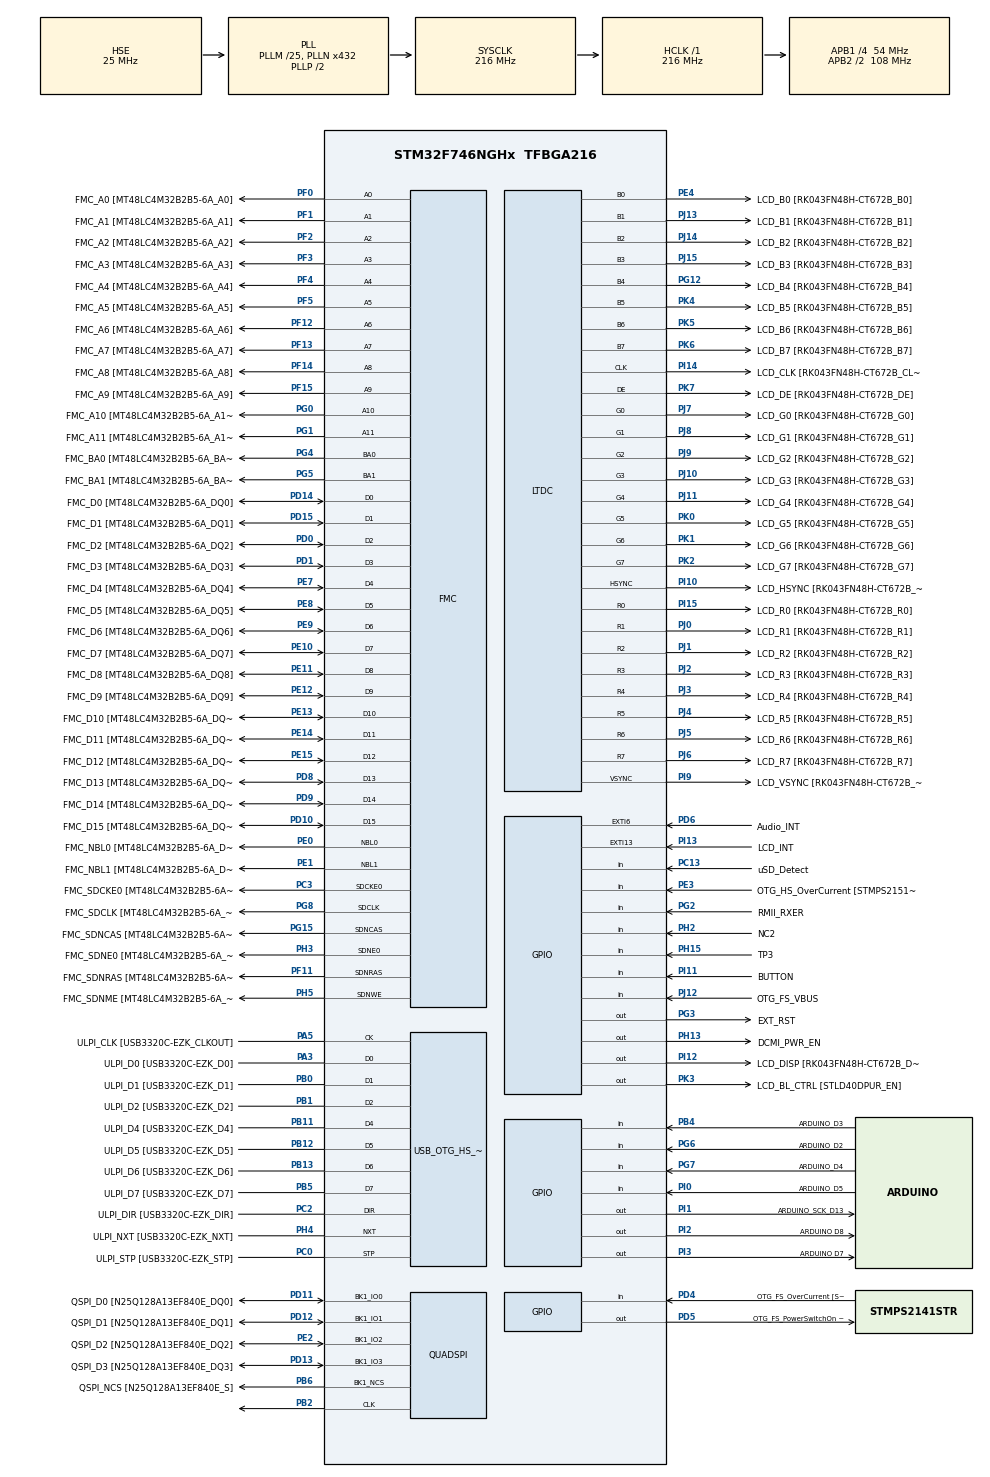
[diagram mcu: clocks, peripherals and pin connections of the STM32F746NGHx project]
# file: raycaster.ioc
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CORTEX_M7.ART_ACCELERATOR_ENABLE=1
CORTEX_M7.CPU_DCache=Enabled
CORTEX_M7.CPU_ICache=Enabled
CORTEX_M7.FlashInterface=TCM_Enabled
DMA2D.ColorMode=DMA2D_OUTPUT_RGB565
FMC.CASLatency1=FMC_SDRAM_CAS_LATENCY_3
FMC.ExitSelfRefreshDelay1=7
FMC.LoadToActiveDelay1=2
FMC.RCDDelay1=2
FMC.RPDelay1=2
FMC.RPDelay2=2
FMC.ReadBurst1=FMC_SDRAM_RBURST_ENABLE
FMC.ReadBurst2=FMC_SDRAM_RBURST_ENABLE
FMC.RowCycleDelay1=7
FMC.RowCycleDelay2=7
FMC.SDClockPeriod1=FMC_SDRAM_CLOCK_PERIOD_2
FMC.SDClockPeriod2=FMC_SDRAM_CLOCK_PERIOD_2
FMC.SelfRefreshTime1=4
FMC.WriteRecoveryTime1=3
LTDC.ActiveH=272
LTDC.ActiveW=480
LTDC.Alpha_L0=255
LTDC.BlendingFactor1_L0=LTDC_BLENDING_FACTOR1_PAxCA
LTDC.BlendingFactor2_L0=LTDC_BLENDING_FACTOR2_PAxCA
LTDC.Blue=0
LTDC.FBStartAdress_L0=0xC0000000
LTDC.Green=0
LTDC.HBP=13
LTDC.HFP=32
LTDC.HSync=41
LTDC.ImageHeight_L0=272
LTDC.ImageWidth_L0=480
LTDC.Layers=0
LTDC.PixelFormat_L0=LTDC_PIXEL_FORMAT_RGB888
LTDC.Red=0
LTDC.VSync=10
LTDC.WindowX1_L0=480
LTDC.WindowY1_L0=272
Mcu.Family=STM32F7
Mcu.Name=STM32F746NGHx
Mcu.Package=TFBGA216
NVIC.DMA2D_IRQn=true\:0\:0\:false\:false\:true\:true\:true\:true
NVIC.LTDC_IRQn=true\:0\:0\:false\:false\:true\:true\:true\:true
NVIC.PriorityGroup=NVIC_PRIORITYGROUP_4
NVIC.TIM6_DAC_IRQn=true\:15\:0\:false\:false\:true\:false\:true\:true
NVIC.TimeBase=TIM6_DAC_IRQn
NVIC.TimeBaseIP=TIM6
PA0/WKUP.GPIO_Label=ARDUINO A0
PA0/WKUP.GPIO_Mode=GPIO_MODE_ANALOG
PA0/WKUP.GPIO_PuPd=GPIO_NOPULL
PA0/WKUP.Signal=ADCx_IN0
PA1.GPIO_Label=RMII_REF_CLK [LAN8742A-CZ-TR_REFCLK0]
PA1.Signal=ETH_REF_CLK
PA10.GPIO_Label=OTG_FS_ID
PA10.Signal=USB_OTG_FS_ID
PA11.GPIO_Label=OTG_FS_N
PA11.Signal=USB_OTG_FS_DM
PA12.GPIO_Label=OTG_FS_P
PA12.Signal=USB_OTG_FS_DP
PA13.GPIO_Label=SWDIO
PA13.Mode=Serial_Wire
PA13.Signal=SYS_JTMS-SWDIO
PA14.GPIO_Label=SWCLK
PA14.Mode=Serial_Wire
PA14.Signal=SYS_JTCK-SWCLK
PA15.GPIO_Label=ARDUINO PWM/D9
PA15.GPIO_ModeDefaultPP=GPIO_MODE_AF_PP
PA15.GPIO_PuPd=GPIO_NOPULL
PA15.GPIO_Speed=GPIO_SPEED_FREQ_LOW
PA15.Signal=S_TIM2_CH1_ETR
PA2.GPIO_Label=RMII_MDIO [LAN8742A-CZ-TR_MDIO]
PA2.Signal=ETH_MDIO
PA3.GPIO_Label=ULPI_D0 [USB3320C-EZK_D0]
PA3.Mode=Host_HS
PA3.Signal=USB_OTG_HS_ULPI_D0
PA4.GPIO_Label=DCMI_HSYNC
PA4.Signal=DCMI_HSYNC
PA5.GPIO_Label=ULPI_CLK [USB3320C-EZK_CLKOUT]
PA5.Mode=Host_HS
PA5.Signal=USB_OTG_HS_ULPI_CK
PA6.Signal=DCMI_PIXCLK
PA7.GPIO_Label=RMII_CRS_DV [LAN8742A-CZ-TR_CRS_DV]
PA7.Signal=ETH_CRS_DV
PA8.GPIO_Label=ARDUINO PWM/D10
PA8.GPIO_ModeDefaultPP=GPIO_MODE_AF_PP
PA8.GPIO_PuPd=GPIO_NOPULL
PA8.GPIO_Speed=GPIO_SPEED_FREQ_LOW
PA8.Signal=S_TIM1_CH1
PA9.GPIO_Label=VCP_TX [STM32F103CBT6_PA3]
PA9.GPIO_Mode=GPIO_MODE_AF_PP
PA9.GPIO_PuPd=GPIO_NOPULL
PA9.GPIO_Speed=GPIO_SPEED_FREQ_LOW
PA9.Signal=USART1_TX
PB0.GPIO_Label=ULPI_D1 [USB3320C-EZK_D1]
PB0.Mode=Host_HS
PB0.Signal=USB_OTG_HS_ULPI_D1
PB1.GPIO_Label=ULPI_D2 [USB3320C-EZK_D2]
PB1.Mode=Host_HS
PB1.Signal=USB_OTG_HS_ULPI_D2
PB10.GPIO_Label=ULPI_D3 [USB3320C-EZK_D3]
PB10.Signal=USB_OTG_HS_ULPI_D3
PB11.GPIO_Label=ULPI_D4 [USB3320C-EZK_D4]
PB11.Mode=Host_HS
PB11.Signal=USB_OTG_HS_ULPI_D4
PB12.GPIO_Label=ULPI_D5 [USB3320C-EZK_D5]
PB12.Mode=Host_HS
PB12.Signal=USB_OTG_HS_ULPI_D5
PB13.GPIO_Label=ULPI_D6 [USB3320C-EZK_D6]
PB13.Mode=Host_HS
PB13.Signal=USB_OTG_HS_ULPI_D6
PB14.GPIO_Label=ARDUINO MISO/D12
PB14.GPIO_Mode=GPIO_MODE_AF_PP
PB14.GPIO_PuPd=GPIO_NOPULL
PB14.GPIO_Speed=GPIO_SPEED_FREQ_LOW
PB14.Signal=SPI2_MISO
PB15.GPIO_Label=ARDUINO MOSI/PWM/D11
PB15.GPIO_Mode=GPIO_MODE_AF_PP
PB15.GPIO_PuPd=GPIO_NOPULL
PB15.GPIO_Speed=GPIO_SPEED_FREQ_LOW
PB15.Signal=SPI2_MOSI
PB2.Mode=Single Bank 1
PB2.Signal=QUADSPI_CLK
PB3.GPIO_Label=SWO
PB3.Signal=SYS_JTDO-SWO
PB4.GPIO_Label=ARDUINO_D3
PB4.Signal=GPIO_Input
PB5.GPIO_Label=ULPI_D7 [USB3320C-EZK_D7]
PB5.Mode=Host_HS
PB5.Signal=USB_OTG_HS_ULPI_D7
PB6.GPIO_Label=QSPI_NCS [N25Q128A13EF840E_S]
PB6.Mode=Single Bank 1
PB6.Signal=QUADSPI_BK1_NCS
PB7.GPIO_Label=VCP_RX [STM32F103CBT6_PA2]
PB7.GPIO_Mode=GPIO_MODE_AF_PP
PB7.GPIO_PuPd=GPIO_NOPULL
PB7.GPIO_Speed=GPIO_SPEED_FREQ_LOW
PB7.Signal=USART1_RX
PB8.GPIO_Label=ARDUINO SCL/D15
PB8.GPIO_Mode=GPIO_MODE_AF_OD
PB8.GPIO_Pu=GPIO_PULLUP
PB8.GPIO_PuPd=GPIO_NOPULL
PB8.GPIO_Speed=GPIO_SPEED_FREQ_LOW
PB8.Signal=I2C1_SCL
PB9.GPIO_Label=ARDUINO SDA/D14
PB9.GPIO_Mode=GPIO_MODE_AF_OD
PB9.GPIO_Pu=GPIO_PULLUP
PB9.GPIO_PuPd=GPIO_NOPULL
PB9.GPIO_Speed=GPIO_SPEED_FREQ_LOW
PB9.Signal=I2C1_SDA
PC0.GPIO_Label=ULPI_STP [USB3320C-EZK_STP]
PC0.Mode=Host_HS
PC0.Signal=USB_OTG_HS_ULPI_STP
PC1.GPIO_Label=RMII_MDC [LAN8742A-CZ-TR_MDC]
PC1.Signal=ETH_MDC
PC10.GPIO_Label=SDMMC_D2
PC10.Signal=SDMMC1_D2
PC11.GPIO_Label=SDMMC_D3
PC11.Signal=SDMMC1_D3
PC12.GPIO_Label=SDMMC_CK
PC12.Signal=SDMMC1_CK
PC13.GPIO_Label=uSD_Detect
PC13.Signal=GPIO_Input
PC14/OSC32_IN.GPIO_Label=RCC_OSC32_IN
PC14/OSC32_IN.Mode=LSE-External-Oscillator
PC14/OSC32_IN.Signal=RCC_OSC32_IN
PC15/OSC32_OUT.GPIO_Label=RCC_OSC32_OUT
PC15/OSC32_OUT.Mode=LSE-External-Oscillator
PC15/OSC32_OUT.Signal=RCC_OSC32_OUT
PC2.GPIO_Label=ULPI_DIR [USB3320C-EZK_DIR]
PC2.Mode=Host_HS
PC2.Signal=USB_OTG_HS_ULPI_DIR
PC3.GPIO_Label=FMC_SDCKE0 [MT48LC4M32B2B5-6A_CKE]
PC3.Mode=SdramChipSelect1_1
PC3.Signal=FMC_SDCKE0
PC4.GPIO_Label=RMII_RXD0 [LAN8742A-CZ-TR_RXD0]
PC4.Signal=ETH_RXD0
PC5.GPIO_Label=RMII_RXD1 [LAN8742A-CZ-TR_RXD1]
PC5.Signal=ETH_RXD1
PC6.GPIO_Label=ARDUINO TX/D1
PC6.Signal=USART6_TX
PC7.GPIO_Label=ARDUINO RX/D0
PC7.Signal=USART6_RX
PC8.Signal=SDMMC1_D0
PC9.Signal=SDMMC1_D1
PD0.GPIO_Label=FMC_D2 [MT48LC4M32B2B5-6A_DQ2]
PD0.Signal=FMC_D2_DA2
PD1.GPIO_Label=FMC_D3 [MT48LC4M32B2B5-6A_DQ3]
PD1.Signal=FMC_D3_DA3
PD10.GPIO_Label=FMC_D15 [MT48LC4M32B2B5-6A_DQ15]
PD10.Signal=FMC_D15_DA15
PD11.GPIO_Label=QSPI_D0 [N25Q128A13EF840E_DQ0]
PD11.Mode=Single Bank 1
PD11.Signal=QUADSPI_BK1_IO0
PD12.GPIO_Label=QSPI_D1 [N25Q128A13EF840E_DQ1]
PD12.Mode=Single Bank 1
PD12.Signal=QUADSPI_BK1_IO1
PD13.GPIO_Label=QSPI_D3 [N25Q128A13EF840E_DQ3]
PD13.Mode=Single Bank 1
PD13.Signal=QUADSPI_BK1_IO3
PD14.GPIO_Label=FMC_D0 [MT48LC4M32B2B5-6A_DQ0]
PD14.Signal=FMC_D0_DA0
PD15.GPIO_Label=FMC_D1 [MT48LC4M32B2B5-6A_DQ1]
PD15.Signal=FMC_D1_DA1
PD2.GPIO_Label=SDMMC_CMD
PD2.GPIO_Speed_High_Default=GPIO_SPEED_FREQ_VERY_HIGH
PD2.Signal=SDMMC1_CMD
PD3.GPIO_Label=DCMI_D5
PD3.Signal=DCMI_D5
PD4.GPIO_Label=OTG_FS_OverCurrent [STMPS2141STR_Fault]
PD4.Signal=GPIO_Input
PD5.GPIO_Label=OTG_FS_PowerSwitchOn [STMPS2141STR_EN]
PD5.PinState=GPIO_PIN_SET
PD5.Signal=GPIO_Output
PD6.GPIO_Label=Audio_INT
PD6.GPIO_ModeDefaultEXTI=GPIO_MODE_EVT_RISING
PD6.Signal=GPXTI6
PD7.GPIO_Label=SPDIF_RX0 [74LVC1G04SE_4]
PD7.Signal=SPDIFRX_IN0
PD8.GPIO_Label=FMC_D13 [MT48LC4M32B2B5-6A_DQ13]
PD8.Signal=FMC_D13_DA13
PD9.GPIO_Label=FMC_D14 [MT48LC4M32B2B5-6A_DQ14]
PD9.Signal=FMC_D14_DA14
PE0.GPIO_Label=FMC_NBL0 [MT48LC4M32B2B5-6A_DQM0]
PE0.Signal=FMC_NBL0
PE1.GPIO_Label=FMC_NBL1 [MT48LC4M32B2B5-6A_DQM1]
PE1.Signal=FMC_NBL1
PE10.GPIO_Label=FMC_D7 [MT48LC4M32B2B5-6A_DQ7]
PE10.Signal=FMC_D7_DA7
PE11.GPIO_Label=FMC_D8 [MT48LC4M32B2B5-6A_DQ8]
PE11.Signal=FMC_D8_DA8
PE12.GPIO_Label=FMC_D9 [MT48LC4M32B2B5-6A_DQ9]
PE12.Signal=FMC_D9_DA9
PE13.GPIO_Label=FMC_D10 [MT48LC4M32B2B5-6A_DQ10]
PE13.Signal=FMC_D10_DA10
PE14.GPIO_Label=FMC_D11 [MT48LC4M32B2B5-6A_DQ11]
PE14.Signal=FMC_D11_DA11
PE15.GPIO_Label=FMC_D12 [MT48LC4M32B2B5-6A_DQ12]
PE15.Signal=FMC_D12_DA12
PE2.GPIO_Label=QSPI_D2 [N25Q128A13EF840E_DQ2]
PE2.Mode=Single Bank 1
PE2.Signal=QUADSPI_BK1_IO2
PE3.GPIO_Label=OTG_HS_OverCurrent [STMPS2151STR_FAULT]
PE3.Signal=GPIO_Input
PE4.GPIO_Label=LCD_B0 [RK043FN48H-CT672B_B0]
PE4.GPIO_Speed=GPIO_SPEED_FREQ_VERY_HIGH
PE4.Mode=RGB888
PE4.Signal=LTDC_B0
PE5.GPIO_Label=DCMI_D6
PE5.Signal=DCMI_D6
PE6.GPIO_Label=DCMI_D7
PE6.Signal=DCMI_D7
PE7.GPIO_Label=FMC_D4 [MT48LC4M32B2B5-6A_DQ4]
PE7.Signal=FMC_D4_DA4
PE8.GPIO_Label=FMC_D5 [MT48LC4M32B2B5-6A_DQ5]
PE8.Signal=FMC_D5_DA5
PE9.GPIO_Label=FMC_D6 [MT48LC4M32B2B5-6A_DQ6]
PE9.Signal=FMC_D6_DA6
PF0.GPIO_Label=FMC_A0 [MT48LC4M32B2B5-6A_A0]
PF0.Signal=FMC_A0
PF1.GPIO_Label=FMC_A1 [MT48LC4M32B2B5-6A_A1]
PF1.Signal=FMC_A1
PF10.GPIO_Label=ARDUINO A1
PF10.GPIO_Mode=GPIO_MODE_ANALOG
PF10.GPIO_PuPd=GPIO_NOPULL
PF10.Signal=ADC3_IN8
PF11.GPIO_Label=FMC_SDNRAS [MT48LC4M32B2B5-6A_RAS]
PF11.Signal=FMC_SDNRAS
PF12.GPIO_Label=FMC_A6 [MT48LC4M32B2B5-6A_A6]
PF12.Signal=FMC_A6
PF13.GPIO_Label=FMC_A7 [MT48LC4M32B2B5-6A_A7]
PF13.Signal=FMC_A7
PF14.GPIO_Label=FMC_A8 [MT48LC4M32B2B5-6A_A8]
PF14.Signal=FMC_A8
PF15.GPIO_Label=FMC_A9 [MT48LC4M32B2B5-6A_A9]
PF15.Signal=FMC_A9
PF2.GPIO_Label=FMC_A2 [MT48LC4M32B2B5-6A_A2]
PF2.Signal=FMC_A2
PF3.GPIO_Label=FMC_A3 [MT48LC4M32B2B5-6A_A3]
PF3.Signal=FMC_A3
PF4.GPIO_Label=FMC_A4 [MT48LC4M32B2B5-6A_A4]
PF4.Signal=FMC_A4
PF5.GPIO_Label=FMC_A5 [MT48LC4M32B2B5-6A_A5]
PF5.Signal=FMC_A5
PF6.GPIO_Label=ARDUINO A5
PF6.GPIO_Mode=GPIO_MODE_ANALOG
PF6.GPIO_PuPd=GPIO_NOPULL
PF6.Signal=ADC3_IN4
PF7.GPIO_Label=ARDUINO A4
PF7.GPIO_Mode=GPIO_MODE_ANALOG
PF7.GPIO_PuPd=GPIO_NOPULL
PF7.Signal=ADC3_IN5
PF8.GPIO_Label=ARDUINO A3
PF8.GPIO_Mode=GPIO_MODE_ANALOG
PF8.GPIO_PuPd=GPIO_NOPULL
PF8.Signal=ADC3_IN6
PF9.GPIO_Label=ARDUINO A2
PF9.GPIO_Mode=GPIO_MODE_ANALOG
PF9.GPIO_PuPd=GPIO_NOPULL
PF9.Signal=ADC3_IN7
PG0.GPIO_Label=FMC_A10 [MT48LC4M32B2B5-6A_A10]
PG0.Signal=FMC_A10
PG1.GPIO_Label=FMC_A11 [MT48LC4M32B2B5-6A_A11]
PG1.Signal=FMC_A11
PG10.GPIO_Label=SAI2_SDB [WM8994ECS/R_ADCDAT1]
PG10.Signal=SAI2_SD_B
PG11.GPIO_Label=RMII_TX_EN [LAN8742A-CZ-TR_TXEN]
PG11.Signal=ETH_TX_EN
PG12.GPIO_Label=LCD_B4 [RK043FN48H-CT672B_B4]
PG12.GPIO_Speed=GPIO_SPEED_FREQ_VERY_HIGH
PG12.Mode=RGB888
PG12.Signal=LTDC_B4
PG13.GPIO_Label=RMII_TXD0 [LAN8742A-CZ-TR_TXD0]
PG13.Signal=ETH_TXD0
PG14.GPIO_Label=RMII_TXD1 [LAN8742A-CZ-TR_TXD1]
PG14.Signal=ETH_TXD1
PG15.GPIO_Label=FMC_SDNCAS [MT48LC4M32B2B5-6A_CAS]
PG15.Signal=FMC_SDNCAS
PG2.GPIO_Label=RMII_RXER
PG2.Signal=GPIO_Input
PG3.GPIO_Label=EXT_RST
PG3.Signal=GPIO_Output
PG4.GPIO_Label=FMC_BA0 [MT48LC4M32B2B5-6A_BA0]
PG4.Signal=FMC_A14_BA0
PG5.GPIO_Label=FMC_BA1 [MT48LC4M32B2B5-6A_BA1]
PG5.Signal=FMC_A15_BA1
PG6.GPIO_Label=ARDUINO_D2
PG6.Signal=GPIO_Input
PG7.GPIO_Label=ARDUINO_D4
PG7.Signal=GPIO_Input
PG8.GPIO_Label=FMC_SDCLK [MT48LC4M32B2B5-6A_CLK]
PG8.Signal=FMC_SDCLK
PG9.GPIO_Label=DCMI_VSYNC
PG9.Signal=DCMI_VSYNC
PH0/OSC_IN.GPIO_Label=OSC_25M [NZ2520SB-25.00M_OUT]
PH0/OSC_IN.Mode=HSE-External-Oscillator
PH0/OSC_IN.Signal=RCC_OSC_IN
PH1/OSC_OUT.Mode=HSE-External-Oscillator
PH1/OSC_OUT.Signal=RCC_OSC_OUT
PH10.GPIO_Label=DCMI_D1
PH10.Signal=DCMI_D1
PH11.GPIO_Label=DCMI_D2
PH11.Signal=DCMI_D2
PH12.GPIO_Label=DCMI_D3
PH12.Signal=DCMI_D3
PH13.GPIO_Label=DCMI_PWR_EN
PH13.Signal=GPIO_Output
PH14.GPIO_Label=DCMI_D4
PH14.Signal=DCMI_D4
PH15.GPIO_Label=TP3
PH15.Signal=GPIO_Input
PH2.GPIO_Label=NC2
PH2.Signal=GPIO_Input
PH3.GPIO_Label=FMC_SDNE0 [MT48LC4M32B2B5-6A_CS]
PH3.Mode=SdramChipSelect1_1
PH3.Signal=FMC_SDNE0
PH4.GPIO_Label=ULPI_NXT [USB3320C-EZK_NXT]
PH4.Mode=Host_HS
PH4.Signal=USB_OTG_HS_ULPI_NXT
PH5.GPIO_Label=FMC_SDNME [MT48LC4M32B2B5-6A_WE]
PH5.Signal=FMC_SDNWE
PH6.GPIO_Label=ARDUINO PWM/D6
PH6.Signal=S_TIM12_CH1
PH7.GPIO_Label=LCD_SCL [RK043FN48H-CT672B_SCL]
PH7.GPIO_Pu=GPIO_PULLUP
PH7.Signal=I2C3_SCL
PH8.GPIO_Label=LCD_SDA [RK043FN48H-CT672B_SDA]
PH8.GPIO_Pu=GPIO_PULLUP
PH8.Signal=I2C3_SDA
PH9.GPIO_Label=DCMI_D0
PH9.Signal=DCMI_D0
PI0.GPIO_Label=ARDUINO_D5
PI0.Signal=GPIO_Input
PI1.GPIO_Label=ARDUINO_SCK_D13
PI1.PinState=GPIO_PIN_SET
PI1.Signal=GPIO_Output
PI10.GPIO_Label=LCD_HSYNC [RK043FN48H-CT672B_HSYNC]
PI10.GPIO_Speed=GPIO_SPEED_FREQ_VERY_HIGH
PI10.Mode=RGB888
PI10.Signal=LTDC_HSYNC
PI11.GPIO_Label=BUTTON
PI11.Signal=GPIO_Input
PI12.GPIO_Label=LCD_DISP [RK043FN48H-CT672B_DISP] 
PI12.PinState=GPIO_PIN_SET
PI12.Signal=GPIO_Output
PI13.GPIO_Label=LCD_INT
PI13.GPIO_ModeDefaultEXTI=GPIO_MODE_EVT_RISING
PI13.Signal=GPXTI13
PI14.GPIO_Label=LCD_CLK [RK043FN48H-CT672B_CLK]
PI14.GPIO_Speed=GPIO_SPEED_FREQ_VERY_HIGH
PI14.Mode=RGB888
PI14.Signal=LTDC_CLK
PI15.GPIO_Label=LCD_R0 [RK043FN48H-CT672B_R0]
PI15.GPIO_Speed=GPIO_SPEED_FREQ_VERY_HIGH
PI15.Mode=RGB888
PI15.Signal=LTDC_R0
PI2.GPIO_Label=ARDUINO D8
PI2.Signal=GPIO_Output
PI3.GPIO_Label=ARDUINO D7
PI3.Signal=GPIO_Output
PI4.GPIO_Label=SAI2_MCLKA [WM8994ECS/R_MCLK1]
PI4.Signal=SAI2_MCLK_A
PI5.GPIO_Label=SAI2_SCKA [WM8994ECS/R_BCLK1]
PI5.Signal=SAI2_SCK_A
PI6.GPIO_Label=SAI2_SDA [WM8994ECS/R_DACDAT1]
PI6.Signal=SAI2_SD_A
PI7.GPIO_Label=SAI2_FSA [WM8994ECS/R_LRCLK1]
PI7.Signal=SAI2_FS_A
PI8.GPIO_Label=NC1 [TP2]
PI8.Signal=RTC_TS
PI9.GPIO_Label=LCD_VSYNC [RK043FN48H-CT672B_VSYNC]
PI9.GPIO_Speed=GPIO_SPEED_FREQ_VERY_HIGH
PI9.Mode=RGB888
PI9.Signal=LTDC_VSYNC
PJ0.GPIO_Label=LCD_R1 [RK043FN48H-CT672B_R1]
PJ0.GPIO_Speed=GPIO_SPEED_FREQ_VERY_HIGH
PJ0.Mode=RGB888
PJ0.Signal=LTDC_R1
PJ1.GPIO_Label=LCD_R2 [RK043FN48H-CT672B_R2]
PJ1.GPIO_Speed=GPIO_SPEED_FREQ_VERY_HIGH
PJ1.Mode=RGB888
PJ1.Signal=LTDC_R2
PJ10.GPIO_Label=LCD_G3 [RK043FN48H-CT672B_G3]
PJ10.GPIO_Speed=GPIO_SPEED_FREQ_VERY_HIGH
PJ10.Mode=RGB888
PJ10.Signal=LTDC_G3
PJ11.GPIO_Label=LCD_G4 [RK043FN48H-CT672B_G4]
PJ11.GPIO_Speed=GPIO_SPEED_FREQ_VERY_HIGH
PJ11.Mode=RGB888
PJ11.Signal=LTDC_G4
PJ12.GPIO_Label=OTG_FS_VBUS
PJ12.Signal=GPIO_Input
PJ13.GPIO_Label=LCD_B1 [RK043FN48H-CT672B_B1]
PJ13.GPIO_Speed=GPIO_SPEED_FREQ_VERY_HIGH
PJ13.Mode=RGB888
PJ13.Signal=LTDC_B1
PJ14.GPIO_Label=LCD_B2 [RK043FN48H-CT672B_B2]
PJ14.GPIO_Speed=GPIO_SPEED_FREQ_VERY_HIGH
PJ14.Mode=RGB888
PJ14.Signal=LTDC_B2
PJ15.GPIO_Label=LCD_B3 [RK043FN48H-CT672B_B3]
PJ15.GPIO_Speed=GPIO_SPEED_FREQ_VERY_HIGH
PJ15.Mode=RGB888
PJ15.Signal=LTDC_B3
PJ2.GPIO_Label=LCD_R3 [RK043FN48H-CT672B_R3]
PJ2.GPIO_Speed=GPIO_SPEED_FREQ_VERY_HIGH
PJ2.Mode=RGB888
PJ2.Signal=LTDC_R3
PJ3.GPIO_Label=LCD_R4 [RK043FN48H-CT672B_R4]
PJ3.GPIO_Speed=GPIO_SPEED_FREQ_VERY_HIGH
PJ3.Mode=RGB888
PJ3.Signal=LTDC_R4
PJ4.GPIO_Label=LCD_R5 [RK043FN48H-CT672B_R5]
PJ4.GPIO_Speed=GPIO_SPEED_FREQ_VERY_HIGH
PJ4.Mode=RGB888
PJ4.Signal=LTDC_R5
PJ5.GPIO_Label=LCD_R6 [RK043FN48H-CT672B_R6]
PJ5.GPIO_Speed=GPIO_SPEED_FREQ_VERY_HIGH
PJ5.Mode=RGB888
PJ5.Signal=LTDC_R6
PJ6.GPIO_Label=LCD_R7 [RK043FN48H-CT672B_R7]
PJ6.GPIO_Speed=GPIO_SPEED_FREQ_VERY_HIGH
PJ6.Mode=RGB888
PJ6.Signal=LTDC_R7
PJ7.GPIO_Label=LCD_G0 [RK043FN48H-CT672B_G0]
PJ7.GPIO_Speed=GPIO_SPEED_FREQ_VERY_HIGH
PJ7.Mode=RGB888
PJ7.Signal=LTDC_G0
PJ8.GPIO_Label=LCD_G1 [RK043FN48H-CT672B_G1]
PJ8.GPIO_Speed=GPIO_SPEED_FREQ_VERY_HIGH
PJ8.Mode=RGB888
PJ8.Signal=LTDC_G1
PJ9.GPIO_Label=LCD_G2 [RK043FN48H-CT672B_G2]
PJ9.GPIO_Speed=GPIO_SPEED_FREQ_VERY_HIGH
PJ9.Mode=RGB888
PJ9.Signal=LTDC_G2
PK0.GPIO_Label=LCD_G5 [RK043FN48H-CT672B_G5]
PK0.GPIO_Speed=GPIO_SPEED_FREQ_VERY_HIGH
PK0.Mode=RGB888
PK0.Signal=LTDC_G5
PK1.GPIO_Label=LCD_G6 [RK043FN48H-CT672B_G6]
PK1.GPIO_Speed=GPIO_SPEED_FREQ_VERY_HIGH
PK1.Mode=RGB888
PK1.Signal=LTDC_G6
PK2.GPIO_Label=LCD_G7 [RK043FN48H-CT672B_G7]
PK2.GPIO_Speed=GPIO_SPEED_FREQ_VERY_HIGH
PK2.Mode=RGB888
PK2.Signal=LTDC_G7
PK3.GPIO_Label=LCD_BL_CTRL [STLD40DPUR_EN]
PK3.GPIO_Speed=GPIO_SPEED_FREQ_LOW
PK3.PinState=GPIO_PIN_SET
PK3.Signal=GPIO_Output
PK4.GPIO_Label=LCD_B5 [RK043FN48H-CT672B_B5]
PK4.GPIO_Speed=GPIO_SPEED_FREQ_VERY_HIGH
PK4.Mode=RGB888
PK4.Signal=LTDC_B5
PK5.GPIO_Label=LCD_B6 [RK043FN48H-CT672B_B6]
PK5.GPIO_Speed=GPIO_SPEED_FREQ_VERY_HIGH
PK5.Mode=RGB888
PK5.Signal=LTDC_B6
PK6.GPIO_Label=LCD_B7 [RK043FN48H-CT672B_B7]
PK6.GPIO_Speed=GPIO_SPEED_FREQ_VERY_HIGH
PK6.Mode=RGB888
PK6.Signal=LTDC_B7
PK7.GPIO_Label=LCD_DE [RK043FN48H-CT672B_DE]
PK7.GPIO_Speed=GPIO_SPEED_FREQ_VERY_HIGH
PK7.Mode=RGB888
PK7.Signal=LTDC_DE
ProjectManager.HeapSize=0x200
ProjectManager.StackSize=0x400
ProjectManager.TargetToolchain=STM32CubeIDE
QUADSPI.ChipSelectHighTime=QSPI_CS_HIGH_TIME_6_CYCLE
QUADSPI.ClockPrescaler=1
QUADSPI.FifoThreshold=4
QUADSPI.FlashSize=24
QUADSPI.SampleShifting=QSPI_SAMPLE_SHIFTING_HALFCYCLE
RCC.AHBFreq_Value=216000000
RCC.APB1CLKDivider=RCC_HCLK_DIV4
RCC.APB1Freq_Value=54000000
RCC.APB1TimFreq_Value=108000000
RCC.APB2CLKDivider=RCC_HCLK_DIV2
RCC.APB2Freq_Value=108000000
RCC.APB2TimFreq_Value=216000000
RCC.CortexFreq_Value=216000000
RCC.HCLKFreq_Value=216000000
RCC.HSE_VALUE=25000000
RCC.HSI_VALUE=16000000
RCC.PLLI2SN=100
RCC.PLLM=25
RCC.PLLN=432
RCC.PLLQ=9
RCC.PLLSAIN=309
RCC.PLLSAIP=RCC_PLLSAIP_DIV4
RCC.PLLSAIR=4
RCC.PLLSAIRDiv=RCC_PLLSAIDIVR_8
RCC.PLLSourceVirtual=RCC_PLLSOURCE_HSE
RCC.SDMMCClockSelection=RCC_SDMMC1CLKSOURCE_CLK48
RCC.SYSCLKFreq_VALUE=216000000
RCC.SYSCLKSource=RCC_SYSCLKSOURCE_PLLCLK
RCC.USBFreq_Value=48000000
RCC.VCOOutputFreq_Value=432000000
SH.ADCx_IN0.0=ADC3_IN0
SH.FMC_A0.0=FMC_A0,12b-sda1
SH.FMC_A1.0=FMC_A1,12b-sda1
SH.FMC_A10.0=FMC_A10,12b-sda1
SH.FMC_A11.0=FMC_A11,12b-sda1
SH.FMC_A14_BA0.0=FMC_BA0,FourSdramBanks1
SH.FMC_A15_BA1.0=FMC_BA1,FourSdramBanks1
SH.FMC_A2.0=FMC_A2,12b-sda1
SH.FMC_A3.0=FMC_A3,12b-sda1
SH.FMC_A4.0=FMC_A4,12b-sda1
SH.FMC_A5.0=FMC_A5,12b-sda1
SH.FMC_A6.0=FMC_A6,12b-sda1
SH.FMC_A7.0=FMC_A7,12b-sda1
SH.FMC_A8.0=FMC_A8,12b-sda1
SH.FMC_A9.0=FMC_A9,12b-sda1
SH.FMC_D0_DA0.0=FMC_D0,sd-16b-d1
SH.FMC_D10_DA10.0=FMC_D10,sd-16b-d1
SH.FMC_D11_DA11.0=FMC_D11,sd-16b-d1
SH.FMC_D12_DA12.0=FMC_D12,sd-16b-d1
SH.FMC_D13_DA13.0=FMC_D13,sd-16b-d1
SH.FMC_D14_DA14.0=FMC_D14,sd-16b-d1
SH.FMC_D15_DA15.0=FMC_D15,sd-16b-d1
SH.FMC_D1_DA1.0=FMC_D1,sd-16b-d1
SH.FMC_D2_DA2.0=FMC_D2,sd-16b-d1
SH.FMC_D3_DA3.0=FMC_D3,sd-16b-d1
SH.FMC_D4_DA4.0=FMC_D4,sd-16b-d1
SH.FMC_D5_DA5.0=FMC_D5,sd-16b-d1
SH.FMC_D6_DA6.0=FMC_D6,sd-16b-d1
SH.FMC_D7_DA7.0=FMC_D7,sd-16b-d1
SH.FMC_D8_DA8.0=FMC_D8,sd-16b-d1
SH.FMC_D9_DA9.0=FMC_D9,sd-16b-d1
SH.FMC_NBL0.0=FMC_NBL0,Sd2ByteEnable1
SH.FMC_NBL1.0=FMC_NBL1,Sd2ByteEnable1
SH.FMC_SDCLK.0=FMC_SDCLK,12b-sda1
SH.FMC_SDNCAS.0=FMC_SDNCAS,12b-sda1
SH.FMC_SDNRAS.0=FMC_SDNRAS,12b-sda1
SH.FMC_SDNWE.0=FMC_SDNWE,12b-sda1
SH.S_TIM12_CH1.0=TIM12_CH1
SH.S_TIM1_CH1.0=TIM1_CH1
SH.S_TIM2_CH1_ETR.0=TIM2_CH1
VP_DMA2D_VS_DMA2D.Mode=DMA2D_Activate
VP_SYS_VS_tim6.Mode=TIM6
board=STM32F746G-DISCO

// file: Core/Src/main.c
/* USER CODE BEGIN Header */
/**
  ******************************************************************************
  * @file           : main.c
  * @brief          : Main program body
  ******************************************************************************
  * @attention
  *
  * Copyright (c) 2024 STMicroelectronics.
  * All rights reserved.
  *
  * This software is licensed under terms that can be found in the LICENSE file
  * in the root directory of this software component.
  * If no LICENSE file comes with this software, it is provided AS-IS.
  *
  ******************************************************************************
  */
/* USER CODE END Header */
#include "main.h"
#include "ltdc.h"
#include "quadspi.h"
#include "gpio.h"
#include "fmc.h"

/* USER CODE BEGIN Includes */
#include <stdio.h>
#include <stdlib.h>
#include <float.h>
#include <string.h>
#include <math.h>
#include <stdbool.h>
#include "../../Drivers/BSP/STM32746G-Discovery/stm32746g_discovery_lcd.h"
#include "rc_config.h"
#include "map.h"
#include "textures.h"
//#include "trig_lut.h"
/* USER CODE END Includes */

void SystemClock_Config(void);

/* USER CODE BEGIN 0 */
// LEVELS
static unsigned char _currentLevel = 0;
static level_typedef _levels[2] = {LEVEL_00, LEVEL_01};

// PLAYER
static float _pPosX, _pPosY, _pDeltaX, _pDeltaY, _pVelocityX = 0, _pVelocityY = 0;
static int   _pAngle = 0; // Angle in increments of FOV_INCR radians

// LOOKUP TABLES
static float        _fisheyeCosLUT[RAYS], _sinLUT[ANG_RANGE], _cosLUT[ANG_RANGE], _fZLUT[SCREEN_HEIGHT / 2];
static unsigned int _sbLUT[ANG_RANGE];

/* USER CODE END 0 */

int main(void)
{
  /* USER CODE BEGIN 1 */
  _pPosX = _levels[_currentLevel].startX;
  _pPosY = _levels[_currentLevel].startY;
  /* USER CODE END 1 */
/* Enable the CPU Cache */

  /* Enable I-Cache---------------------------------------------------------*/
  SCB_EnableICache();

  /* Enable D-Cache---------------------------------------------------------*/
  SCB_EnableDCache();

  /* MCU Configuration--------------------------------------------------------*/

  /* Reset of all peripherals, Initializes the Flash interface and the Systick. */
  HAL_Init();

  /* Configure the system clock */
  SystemClock_Config();

  /* Initialize all configured peripherals */
  MX_GPIO_Init();
  MX_FMC_Init();
  MX_LTDC_Init();
  MX_QUADSPI_Init();
  /* USER CODE BEGIN 2 */
  BSP_LCD_Init();
  BSP_LCD_LayerRgb565Init(LTDC_FOREGROUND, LCD_FB_START_ADDRESS);
  BSP_LCD_LayerRgb565Init(LTDC_BACKGROUND, LCD_BB_START_ADDRESS);
  BSP_LCD_SetLayerVisible(LTDC_BACKGROUND, DISABLE);
  BSP_LCD_DisplayOn();
  BSP_LCD_SelectLayer(LTDC_BACKGROUND);
  BSP_LCD_SetFont(&Font12);
  BSP_LCD_SelectLayer(LTDC_FOREGROUND);
  BSP_LCD_Clear(LCD_COLOR_BLACK);

  for (int i = 0; i < RAYS; i++) { _fisheyeCosLUT[i] = 1 / cos((RAYS / 2 - i) * ANG_INCR); } // Pre-calculate all cosine values to correct fisheye effect later
  for (int i = 0; i < ANG_RANGE; i++) {
    _sinLUT[i] = -sin(i * ANG_INCR + 0.0001); // Sin is inverted because I use screenspace coordinates so Y is inverted
    _cosLUT[i] =  cos(i * ANG_INCR + 0.0001); // Also why I have a separate cos LUT. While it uses more memory, it is faster because it avoids an expensive modulus operation
    _sbLUT[i]  =  (int)(SKYBOX_SIZE_X - (i + 1) * ANG_INCR * SKYBOX_SCALE_F);
  }
  for (int i = SCREEN_HEIGHT / 2; i < SCREEN_HEIGHT; i++) { _fZLUT[i - SCREEN_HEIGHT / 2] = (SCREEN_HEIGHT / 2 / (float)(i - SCREEN_HEIGHT / 2 + 1)) * LINE_VERTICAL_SCALE; }
  /* USER CODE END 2 */

  /* Infinite loop */
  while (1)
  {

    /* USER CODE BEGIN 3 */
    if (!HAL_GPIO_ReadPin(LCD_VSYNC_GPIO_Port, LCD_VSYNC_Pin)) {
      pageFlip();
      showFPS(cast());

      _pDeltaX = _cosLUT[_pAngle] * _levels[_currentLevel].acceleration;
      _pDeltaY = _sinLUT[_pAngle] * _levels[_currentLevel].acceleration;

      if (HAL_GPIO_ReadPin(ARDUINO_D4_GPIO_Port, ARDUINO_D4_Pin)) { // RIGHT
        _pAngle -= P_LOOK_SPEED;
        if (_pAngle < 0) { _pAngle += ANG_RANGE; }
      }
      else if (HAL_GPIO_ReadPin(ARDUINO_D5_GPIO_Port, ARDUINO_D5_Pin)) { // LEFT
        _pAngle += P_LOOK_SPEED;
        if (_pAngle >= ANG_RANGE) { _pAngle -= ANG_RANGE; }
      }
      if (HAL_GPIO_ReadPin(ARDUINO_D2_GPIO_Port, ARDUINO_D2_Pin)) { // FORWARD
        _pVelocityX += _pDeltaX;
        _pVelocityY += _pDeltaY;
      }
      else if (HAL_GPIO_ReadPin(ARDUINO_D3_GPIO_Port, ARDUINO_D3_Pin)) { // BACKWARD
        _pVelocityX -= _pDeltaX;
        _pVelocityY -= _pDeltaY;
      }

      if (_levels[_currentLevel].map[MAP_WALLS][(int)_pPosY * _levels[_currentLevel].sizeX + (int)(_pPosX + ((_pVelocityX < 0) ? -P_HITBOX_SIZE : P_HITBOX_SIZE))] == 0) { _pPosX += _pVelocityX; }
      if (_levels[_currentLevel].map[MAP_WALLS][(int)(_pPosY + ((_pVelocityY < 0) ? -P_HITBOX_SIZE : P_HITBOX_SIZE)) * _levels[_currentLevel].sizeX + (int)_pPosX] == 0) { _pPosY += _pVelocityY; }

      _pVelocityX *= (1 - _levels[_currentLevel].friction);
      _pVelocityY *= (1 - _levels[_currentLevel].friction);
    }
  }
  /* USER CODE END 3 */
}

void SystemClock_Config(void)
{
  RCC_OscInitTypeDef RCC_OscInitStruct = {0};
  RCC_ClkInitTypeDef RCC_ClkInitStruct = {0};

  /** Configure LSE Drive Capability
  */
  HAL_PWR_EnableBkUpAccess();

  /** Configure the main internal regulator output voltage
  */
  __HAL_RCC_PWR_CLK_ENABLE();
  __HAL_PWR_VOLTAGESCALING_CONFIG(PWR_REGULATOR_VOLTAGE_SCALE1);

  /** Initializes the RCC Oscillators according to the specified parameters
  * in the RCC_OscInitTypeDef structure.
  */
  RCC_OscInitStruct.OscillatorType = RCC_OSCILLATORTYPE_HSE;
  RCC_OscInitStruct.HSEState = RCC_HSE_ON;
  RCC_OscInitStruct.PLL.PLLState = RCC_PLL_ON;
  RCC_OscInitStruct.PLL.PLLSource = RCC_PLLSOURCE_HSE;
  RCC_OscInitStruct.PLL.PLLM = 25;
  RCC_OscInitStruct.PLL.PLLN = 432;
  RCC_OscInitStruct.PLL.PLLP = RCC_PLLP_DIV2;
  RCC_OscInitStruct.PLL.PLLQ = 9;
  if (HAL_RCC_OscConfig(&RCC_OscInitStruct) != HAL_OK)
  {
    Error_Handler();
  }

  /** Activate the Over-Drive mode
  */
  if (HAL_PWREx_EnableOverDrive() != HAL_OK)
  {
    Error_Handler();
  }

  /** Initializes the CPU, AHB and APB buses clocks
  */
  RCC_ClkInitStruct.ClockType = RCC_CLOCKTYPE_HCLK|RCC_CLOCKTYPE_SYSCLK
                              |RCC_CLOCKTYPE_PCLK1|RCC_CLOCKTYPE_PCLK2;
  RCC_ClkInitStruct.SYSCLKSource = RCC_SYSCLKSOURCE_PLLCLK;
  RCC_ClkInitStruct.AHBCLKDivider = RCC_SYSCLK_DIV1;
  RCC_ClkInitStruct.APB1CLKDivider = RCC_HCLK_DIV4;
  RCC_ClkInitStruct.APB2CLKDivider = RCC_HCLK_DIV2;

  if (HAL_RCC_ClockConfig(&RCC_ClkInitStruct, FLASH_LATENCY_7) != HAL_OK)
  {
    Error_Handler();
  }
}

/* USER CODE BEGIN 4 */
int __attribute__((section(".RamFunc"))) cast(void) {
  // Variable prefix convention: r = ray, m = map, p = performance, t = texture, sb = skybox, f = floor
  unsigned int pStartTime = HAL_GetTick();
  int          rAngle;

  BSP_LCD_SelectLayer(LTDC_BACKGROUND);

  rAngle = _pAngle + RAYS / 2;
  if (rAngle >= ANG_RANGE) { rAngle -= ANG_RANGE; }

  for (int rCount = 0; rCount < RAYS; rCount++) {
    // This uses David Ziemkiewicz' method of velocities and times, as well as Lodev's DDA. Massive thanks to both of these legends.
    float       rVelocityX = _cosLUT[rAngle], rVelocityY = _sinLUT[rAngle], rIntersectX = _pPosX, rIntersectY = _pPosY, rTimeX, rTimeY, rLength = 0;
    int         mX = (int)rIntersectX, mY = (int)rIntersectY;
    _Bool       rVelSignX = (rVelocityX > 0), rVelSignY = (rVelocityY > 0);
    signed char rStepX = rVelSignX ? 1 : -1, rStepY = rVelSignY ? 1 : -1, rHitSide = 0;

    for (int i = 0; i < _levels[_currentLevel].sizeX * _levels[_currentLevel].sizeY; i++) {
      if (_levels[_currentLevel].map[MAP_WALLS][mY * _levels[_currentLevel].sizeX + mX] > 0) { break; }

      rTimeX = (mY - rIntersectY + rVelSignY) / rVelocityY; // This should be treated as "time to X-side wall"
      rTimeY = (mX - rIntersectX + rVelSignX) / rVelocityX;

      if (rTimeY < rTimeX) { // Vertical line
        mX += rStepX;
        rIntersectX = mX - !rVelSignX * rStepX;
        rIntersectY += rVelocityY * rTimeY;
        rLength += rTimeY;
        rHitSide = 1;
      }
      else { // Horizontal line
        mY += rStepY;
        rIntersectY = mY - !rVelSignY * rStepY;
        rIntersectX += rVelocityX * rTimeX;
        rLength += rTimeX;
        rHitSide = 0;
      }
    }

    // RENDERING
    float tLineHeight = SCREEN_HEIGHT / rLength * _fisheyeCosLUT[rCount] * LINE_VERTICAL_SCALE;
    if (tLineHeight < SHORTEST_LINE) { tLineHeight = 0; }

    float tX, tY = 0, tYStep = tLineHeight / TEXTURE_SIZE, tOffset = (tLineHeight - SCREEN_HEIGHT) / 2;
    if (rHitSide) { tX = (1 - (rIntersectY - (int)rIntersectY)) * TEXTURE_SIZE; if (rAngle < ANG_RANGE / 4 || rAngle > (ANG_RANGE / 4) * 3) { tX = TEXTURE_SIZE - tX; }}
    else          { tX = (1 - (rIntersectX - (int)rIntersectX)) * TEXTURE_SIZE; if (rAngle < ANG_RANGE / 2)                                 { tX = TEXTURE_SIZE - tX; }}

    if (tLineHeight > SCREEN_HEIGHT) { // Check if line fills up the screen, if it does, drawing the sky and floor is not necessary, so we just draw the wall
      if (rCount % 2 == 0) {
        int tSkipLines = tOffset / tYStep, tFirstLine = tYStep - (tOffset - tSkipLines * tYStep);
        tY = tFirstLine;
        for (int i = tSkipLines; i < TEXTURE_SIZE - tSkipLines; i++) {
          BSP_LCD_SetTextColor(_baseTex[_levels[_currentLevel].map[MAP_WALLS][mY * _levels[_currentLevel].sizeX + mX] - 1 + rHitSide][i * TEXTURE_SIZE + (int)(tX)]);
          if (i != tSkipLines && i != TEXTURE_SIZE - tSkipLines - 1) { BSP_LCD_FillRect((rCount * RECT_Y), tY, RECT_Y * 2, tYStep + 1); tY += tYStep; }
          else { BSP_LCD_FillRect((rCount * RECT_Y), (i == tSkipLines) ? 0 : tY, RECT_Y * 2, tFirstLine + 2); }
        }
      }
    }
    else {
      tOffset *= -1;

      if (rCount % 2 == 0) {
        int sbY = 0, sbDrawLines;
        if (tLineHeight) { sbDrawLines = ((int)(tOffset / SKYBOX_TEXEL_Y) + 1) & (TEXTURE_SIZE - 1); }
        else             { sbDrawLines = SKYBOX_SIZE_Y; }

        // DRAW SKYBOX
        for (int i = 0; i < sbDrawLines; i++) {
          BSP_LCD_SetTextColor(_skyboxTex[_levels[_currentLevel].skybox][i * SKYBOX_SIZE_X + _sbLUT[rAngle]]);
          BSP_LCD_FillRect((rCount * RECT_Y), sbY, RECT_Y * 2, SKYBOX_TEXEL_Y);
          sbY += SKYBOX_TEXEL_Y;
        }

        // DRAW WALLS
        if (tLineHeight) {
          for (int i = 0; i < TEXTURE_SIZE; i++) {
            BSP_LCD_SetTextColor(_baseTex[_levels[_currentLevel].map[MAP_WALLS][mY * _levels[_currentLevel].sizeX + mX] - 1 + rHitSide][i * TEXTURE_SIZE + (int)(tX)]);
            BSP_LCD_FillRect((rCount * RECT_Y), tOffset + tY, RECT_Y * 2, tYStep + 1);
            tY += tYStep;
          }
        }
      }

      // DRAW FLOOR
      for (int i = tOffset + tLineHeight; i < SCREEN_HEIGHT; i += RECT_Y) {
        float fZ = _fZLUT[i - SCREEN_HEIGHT / 2] * _fisheyeCosLUT[rCount], fX = _pPosX + rVelocityX * fZ, fY = _pPosY + rVelocityY * fZ;
        int   fTextureX = (int)(TEXTURE_SIZE * fX) & (TEXTURE_SIZE - 1), fTextureY = (int)(TEXTURE_SIZE * fY) & (TEXTURE_SIZE - 1);
        BSP_LCD_SetTextColor(_baseTex[_levels[_currentLevel].map[MAP_FLOOR][(int)fY * _levels[_currentLevel].sizeX + (int)fX] - 1][fTextureY * TEXTURE_SIZE + fTextureX]);
        BSP_LCD_FillRect((rCount * RECT_Y), i, RECT_Y, RECT_Y);
      }
    }

    rAngle--;
    if (rAngle < 0) { rAngle += ANG_RANGE; }
  }

  return HAL_GetTick() - pStartTime;
}

void pageFlip(void) {
  static volatile unsigned char activeBuffer = 1;
  activeBuffer ^= 1;
  BSP_LCD_SWAP(activeBuffer);
}

void showFPS(unsigned int frameTime) {
  unsigned char frameTimeS[16], frameRateS[10];
  sprintf((char*)frameTimeS, "%02i.%ims", frameTime, frameTime % 10);
  sprintf((char*)frameRateS, "%03ifps", 1000 / frameTime);
  BSP_LCD_SetTextColor(0x001F);
  BSP_LCD_DisplayStringAt(0,  0, frameTimeS, LEFT_MODE);
  BSP_LCD_DisplayStringAt(0, 12, frameRateS, LEFT_MODE);
}
/* USER CODE END 4 */

void HAL_TIM_PeriodElapsedCallback(TIM_HandleTypeDef *htim)
{
  if (htim->Instance == TIM6) {
    HAL_IncTick();
  }
}

void Error_Handler(void)
{
  /* USER CODE BEGIN Error_Handler_Debug */
  /* User can add his own implementation to report the HAL error return state */
  HAL_GPIO_WritePin(ARDUINO_SCK_D13_GPIO_Port, ARDUINO_SCK_D13_Pin, GPIO_PIN_SET);
  __disable_irq();
  while (1)
  {
  }
  /* USER CODE END Error_Handler_Debug */
}
